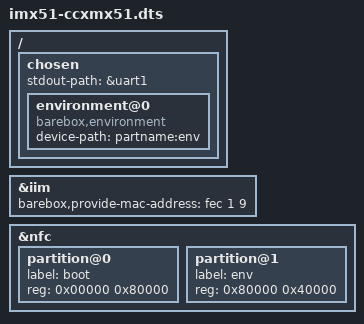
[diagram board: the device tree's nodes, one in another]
#include <arm/imx51-digi-connectcore-jsk.dts>

/ {
	chosen {
		stdout-path = &uart1;

	environment@0 {
		compatible = "barebox,environment";
		device-path = &nfc, "partname:env";
		};
	};
};

&iim {
	barebox,provide-mac-address = <&fec 1 9>;
};

&nfc {
	partition@0 {
		label = "boot";
		reg = <0x00000 0x80000>;
	};

	partition@1 {
		label = "env";
		reg = <0x80000 0x40000>;
	};
};

#include "mm_imx51.dtsi"
